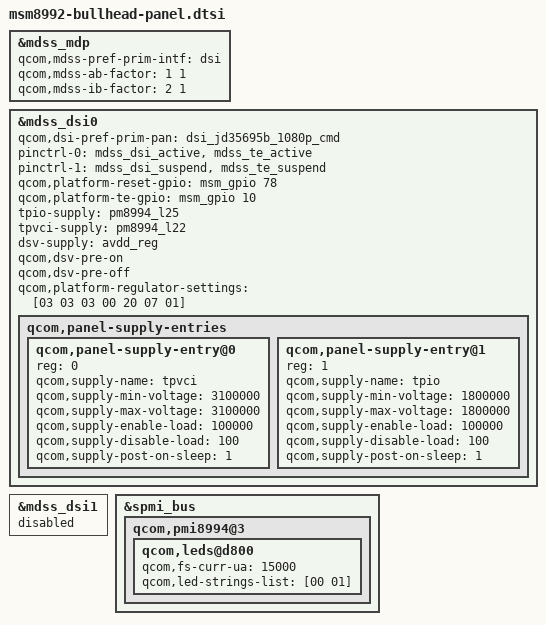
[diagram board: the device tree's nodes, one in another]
/* Copyright (c) 2015, LGE Inc. All rights reserved.
 * Copyright (c) 2014, The Linux Foundation. All rights reserved.
 *
 * This program is free software; you can redistribute it and/or modify
 * it under the terms of the GNU General Public License version 2 and
 * only version 2 as published by the Free Software Foundation.
 *
 * This program is distributed in the hope that it will be useful,
 * but WITHOUT ANY WARRANTY; without even the implied warranty of
 * MERCHANTABILITY or FITNESS FOR A PARTICULAR PURPOSE.  See the
 * GNU General Public License for more details.
 */

#include "dsi-panel-jdi-fhd-video.dtsi"
#include "dsi-panel-jd35695b-1080p-cmd.dtsi"

&mdss_mdp {
	qcom,mdss-pref-prim-intf = "dsi";
	qcom,mdss-ab-factor = <1 1>;
	qcom,mdss-ib-factor = <2 1>;
	/delete-property/ qcom,mdss-ad-off;
};

&mdss_dsi0 {
	qcom,dsi-pref-prim-pan = <&dsi_jd35695b_1080p_cmd>;
	pinctrl-names = "mdss_default", "mdss_sleep";
	pinctrl-0 = <&mdss_dsi_active &mdss_te_active>;
	pinctrl-1 = <&mdss_dsi_suspend &mdss_te_suspend>;

	qcom,platform-reset-gpio = <&msm_gpio 78 0>;
	qcom,platform-te-gpio = <&msm_gpio 10 0>;

	tpio-supply = <&pm8994_l25>;	/* 1V8 */
	tpvci-supply = <&pm8994_l22>;	/* 3V1 */
	dsv-supply = <&avdd_reg>;	/* +/-5V5 */

	qcom,dsv-pre-on;
	qcom,dsv-pre-off;

	qcom,platform-regulator-settings = [03 03 03 00 20 07 01];

	qcom,panel-supply-entries {
		#address-cells = <1>;
		#size-cells = <0>;

		qcom,panel-supply-entry@0 {
			reg = <0>;
			qcom,supply-name = "tpvci";
			qcom,supply-min-voltage = <3100000>;
			qcom,supply-max-voltage = <3100000>;
			qcom,supply-enable-load = <100000>;
			qcom,supply-disable-load = <100>;
			qcom,supply-post-on-sleep = <1>;
		};

		qcom,panel-supply-entry@1 {
			reg = <1>;
			qcom,supply-name = "tpio";
			qcom,supply-min-voltage = <1800000>;
			qcom,supply-max-voltage = <1800000>;
			qcom,supply-enable-load = <100000>;
			qcom,supply-disable-load = <100>;
			qcom,supply-post-on-sleep = <1>;
		};
	};
};

&mdss_dsi1{
	status="disabled";
};

&spmi_bus {
	qcom,pmi8994@3 {
		qcom,leds@d800 {
			qcom,fs-curr-ua = <15000>;
			qcom,led-strings-list = [00 01];
		};
	};
};
